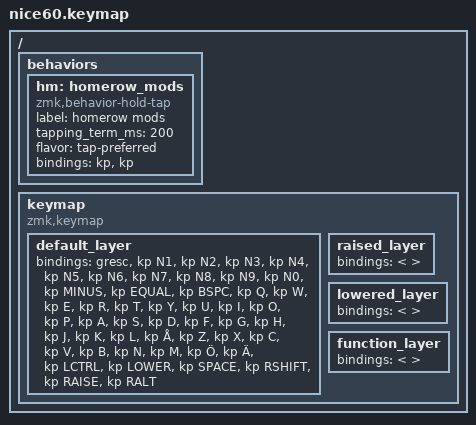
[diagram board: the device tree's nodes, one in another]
/*
 * Copyright (c) 2022 Gabriel Hansson
 *
 * SPDX-License-Identifier: MIT
 */

#include <behaviors.dtsi>
#include <dt-bindings/zmk/keys.h>
// TODO: Suspect some won't be used
#include <dt-bindings/zmk/rgb.h>
#include <dt-bindings/zmk/bt.h>

/ {
	behaviors {
        hm: homerow_mods {
            compatible = "zmk,behavior-hold-tap";
            label = "homerow mods";
            #binding-cells = <2>;
            tapping_term_ms = <200>;
            flavor = "tap-preferred";
            bindings = <&kp>, <&kp>;
        };
    };
	keymap {
		compatible = "zmk,keymap";
		
		// http://www.keyboard-layout-editor.com/#/gists/0e81bf405ebbc268280f0506f7d0e771
		//TODO: do i need to use the standard layer names?
		default_layer {
		/* TODO: 
			binding for Ö Ä Å Lower Raise Lctrl/mod?
			do I need lalt and Rctrl, lshift?
		*/

			bindings = <
	&gresc  &kp N1 &kp N2 &kp N3 &kp N4 &kp N5 &kp N6 &kp N7 &kp N8 &kp N9 &kp N0 &kp MINUS &kp EQUAL  &kp BSPC
	&kp Q &kp W &kp E &kp R &kp T &kp Y &kp U &kp I &kp O &kp P 
	&kp A &kp S &kp D &kp F &kp G &kp H &kp J &kp K &kp L &kp Å
	&kp Z &kp X &kp C &kp V &kp B &kp N &kp M &kp Ö &kp Ä
	&kp LCTRL &kp LOWER &kp SPACE &kp RSHIFT &kp RAISE &kp RALT
			>;
		};

		raised_layer {
			bindings = <
			
			>;
		};

		lowered_layer {
			bindings = <
			
			>;
		};

		function_layer {
			bindings = <
			
			>;
		};
	};
};
